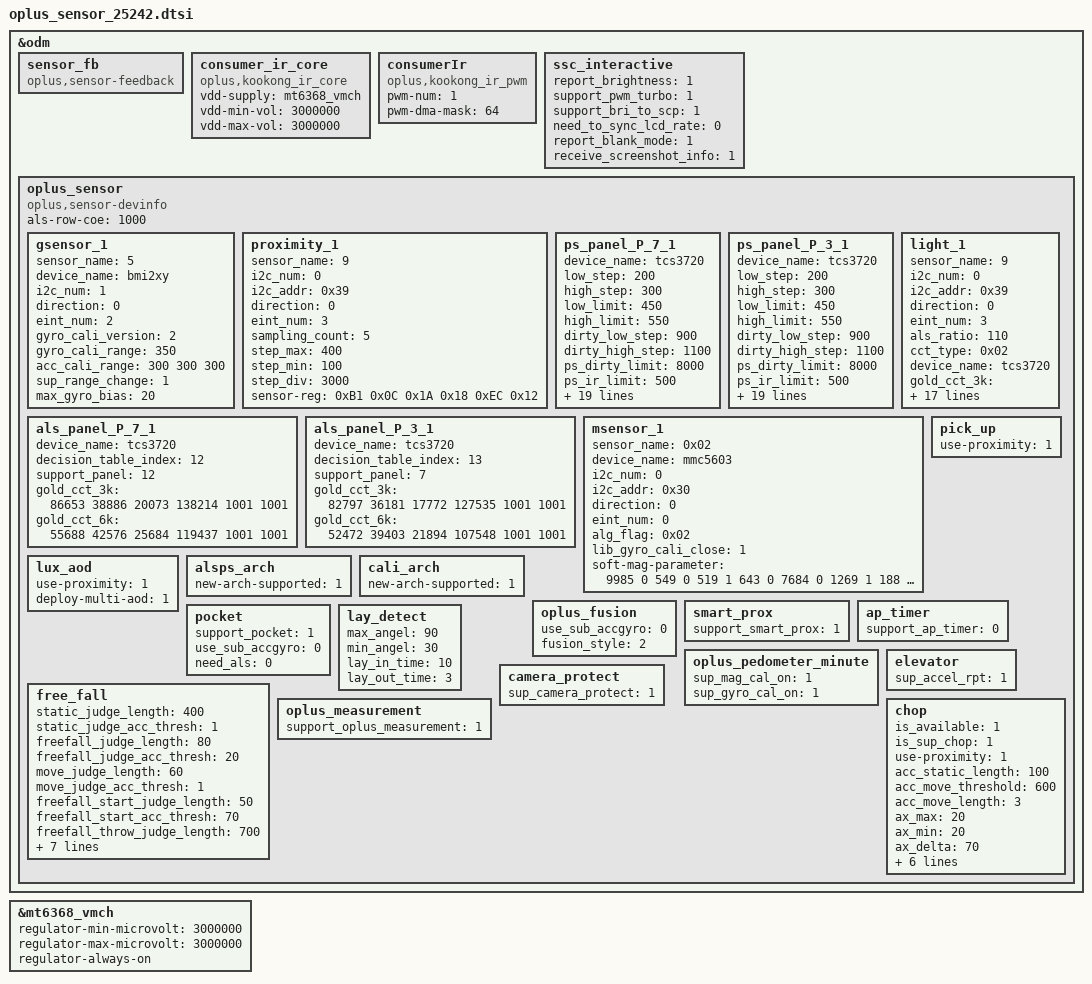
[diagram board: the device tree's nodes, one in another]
&odm {
	sensor_fb: sensor_fb {
		compatible = "oplus,sensor-feedback";
	};
	consumer_ir_core: consumer_ir_core {
		compatible = "oplus,kookong_ir_core";
		status = "okay";
		vdd-supply = <&mt6368_vmch>;
		vdd-min-vol = <3000000>;
		vdd-max-vol = <3000000>;
	};
	consumerIr: consumerIr {
		compatible = "oplus,kookong_ir_pwm";
		status = "okay";
		pwm-num = <1>;
		pwm-dma-mask = <64>;
	};
	ssc_interactive: ssc_interactive {
		report_brightness = <1>;
		support_pwm_turbo = <1>;
		support_bri_to_scp = <1>;
		need_to_sync_lcd_rate = <0>;
		report_blank_mode = <1>;
		receive_screenshot_info = <1>;
	};
	oplus_sensor:oplus_sensor {
		compatible = "oplus,sensor-devinfo";
		als-row-coe = <1000>;
		/* sensor start */
		/*
		enum {
			LIS3DH,
			LSM6DS3,
			BMI160,
			LIS2HH12,
			LSM6DSM,
			BMI2XY,
			LSM6DSO,
			ICM4X6XX,
			ICM4263X,
			ICM4N607,
			BMI22X,
			SC7A20,
			MC34X9,
		};
		*/
		gsensor_1: gsensor_1 {
			status = "okay";
			sensor_name = <5>;//BMI2XY
			device_name = "bmi2xy";
			i2c_num = <1>;
			direction = <0>;
			eint_num = <2>;
			gyro_cali_version= <2>;
			gyro_cali_range =<350>;
			acc_cali_range= <300 300 300>;
			sup_range_change = <1>;
			max_gyro_bias = <20>;
		};

		/*
		enum {
			AKM09911,
			MMC3530,
			MMC5603,
			MXG4300,
			AKM09918,
			AKM09919,
		};
		*/
		/* support_panel: search g_panel_node */
		/*enum panel_id{
			SAMSUNG = 1,
			BOE,
			TIANMA,
			NT36672C,
			HX83112F,
			TM,
			P_3,
			P_B,
			TD4377,
			ILI9883C,
			FT8057P,
			P_7,
			ILI7807S,
			DH_SOFT_LIGHT,
			NT36532W,
			HX,
			PANEL_NUM
		};*/
		proximity_1: proximity_1 {
			status = "okay";
			sensor_name = <9>;//TCS3720
			i2c_num = <0>;
			i2c_addr = <0x39>;
			direction = <0>;
			eint_num = <3>;
			sampling_count = <5>;
			step_max = <400>;
			step_min = <100>;
			step_div = <3000>;
			sensor-reg = <0xB1 0x0C 0x1A 0x18 0xEC 0x12>;
		};
		ps_panel_P_7_1: ps_panel_P_7_1 {
			status = "okay";
			device_name = "tcs3720";
			low_step = <200>;
			high_step = <300>;
			low_limit = <450>;
			high_limit = <550>;
			dirty_low_step = <900>;
			dirty_high_step = <1100>;
			ps_dirty_limit = <8000>;
			ps_ir_limit = <500>;
			ps_adjust_min = <0>;
			ps_adjust_max = <1250>;
			anti_shake_delta = <150>;
			dynamic_cali_max = <5000>;
			raw2offset_radio = <1000>;
			offset_max = <16000>;
			offset_range_min = <0>;
			offset_range_max = <65534>;
			force_cali_limit = <0>;
			cali_jitter_limit = <80>;
			cal_offset_margin = <8000>;
			60hz_psd_us = <2380>;
			90hz_psd_us = <2380>;
			120hz_psd_us = <2380>;
			ps_check_num = <3>;
			ps_mid_filter = <0>;
			need_to_sync_lcd_rate = <0>;
			dmc_flt_thr = <100>;
			ps_power_config = <14>;
		};
		ps_panel_P_3_1: ps_panel_P_3_1 {
			status = "okay";
			device_name = "tcs3720";
			low_step = <200>;
			high_step = <300>;
			low_limit = <450>;
			high_limit = <550>;
			dirty_low_step = <900>;
			dirty_high_step = <1100>;
			ps_dirty_limit = <8000>;
			ps_ir_limit = <500>;
			ps_adjust_min = <0>;
			ps_adjust_max = <1250>;
			anti_shake_delta = <150>;
			dynamic_cali_max = <5000>;
			raw2offset_radio = <1000>;
			offset_max = <16000>;
			offset_range_min = <0>;
			offset_range_max = <65534>;
			force_cali_limit = <0>;
			cali_jitter_limit = <80>;
			cal_offset_margin = <8000>;
			60hz_psd_us = <2380>;
			90hz_psd_us = <2380>;
			120hz_psd_us = <2380>;
			ps_check_num = <3>;
			ps_mid_filter = <0>;
			need_to_sync_lcd_rate = <0>;
			dmc_flt_thr = <100>;
			ps_power_config = <14>;
		};
		light_1: light_1 {
			status = "okay";
			sensor_name = <9>;//TCS3720
			i2c_num = <0>;
			i2c_addr = <0x39>;
			direction = <0>;
			eint_num = <3>;
			als_ratio = <110>;
			cct_type = <0x02>; //0x01 CCT_NORMAL 0x02 CCT_WISE
			device_name = "tcs3720";
			gold_cct_3k = <86653 38886 20073 138214 1001 1001>;
			gold_cct_6k = <55688 42576 25684 119437 1001 1001>;
			lb_bri_max = <4096>;
			ir_ratio = <10>; // *1000
			als_delay = <390>;
			als_delay_60hz = <153>;
			als_delay_90hz = <290>;
			als_delay_120hz = <242>;
			available_sensor = <14>;
			gold_cct_factor = <1000 1000 1000 1000 1000 1000>;
			high_pwm_cct = <1>;
			als_timer_ms = <100>;
			als_buffer_length = <2>;
			need_gain_cali = <1>;
                        scale_gain = <512>;
			fifo_sample_time_switch = <1>;
		};
		als_panel_P_7_1: als_panel_P_7_1 {
			status = "okay";
			device_name = "tcs3720";
			decision_table_index = <12>;
			support_panel = <12>; // 1-SAMSUNG, 2-BOE, 3-TIANMA, 4-NT36672C, 5-HX83112F, 6-TM, 7-P_3, 8-P_B, 9-TD4377, 10-ILI9883C, 11-FT8057P, 12-P_7
			gold_cct_3k = <86653 38886 20073 138214 1001 1001>;
			gold_cct_6k = <55688 42576 25684 119437 1001 1001>;
		};
		als_panel_P_3_1: als_panel_P_3_1 {
			status = "okay";
			device_name = "tcs3720";
			decision_table_index = <13>;
			support_panel = <7>; // 1-SAMSUNG, 2-BOE, 3-TIANMA, 4-NT36672C, 5-HX83112F, 6-TM, 7-P_3, 8-P_B, 9-TD4377, 10-ILI9883C, 11-FT8057P, 12-P_7
			gold_cct_3k = <82797 36181 17772 127535 1001 1001>;
			gold_cct_6k = <52472 39403 21894 107548 1001 1001>;
		};
		msensor_1: msensor_1 {
			status = "okay";
			sensor_name = <0x02>; // MMC5603
			device_name = "mmc5603";
			i2c_num = <0>;
			i2c_addr = <0x30>;
			direction = <0>;
			eint_num = <0>;
			alg_flag = <0x02>;
			lib_gyro_cali_close = <1>;
			soft-mag-parameter = <9985 0 549 0 519 1 643 0 7684 0 1269 1 188 0 145 1 10483 0>;
		};
		pick_up: pick_up {
			status = "okay";
			use-proximity = <1>;
		};
		lux_aod: lux_aod {
			status = "okay";
			use-proximity = <1>;
			deploy-multi-aod = <1>;
		};
		alsps_arch: alsps_arch {
			status = "okay";
			new-arch-supported = <1>;
		};
		cali_arch: cali_arch {
			status = "okay";
			new-arch-supported = <1>;
		};
		oplus_fusion: oplus_fusion {
			status = "okay";
			use_sub_accgyro = <0>;
			fusion_style = <2>; // 0:vendor fusion; 1:oppo fusion; 2:mix fusion
		};
		smart_prox: smart_prox {
			status = "okay";
			support_smart_prox = <1>;
		};
		ap_timer: ap_timer {
			status = "okay";
			support_ap_timer = <0>;
		};
		pocket: pocket {
			status = "okay";
			support_pocket = <1>;
			use_sub_accgyro = <0>;
			need_als = <0>;
		};
		lay_detect: lay_detect{
			status = "okay";
			max_angel = <90>;
			min_angel = <30>;
			lay_in_time = <10>;
			lay_out_time = <3>;
		};
		oplus_pedometer_minute: oplus_pedometer_minute{
			status = "okay";
			sup_mag_cal_on = <1>;
			sup_gyro_cal_on = <1>;
		};
		free_fall: free_fall{
			status = "okay";
			static_judge_length = <400>;
			static_judge_acc_thresh = <1>;
			freefall_judge_length = <80>;
			freefall_judge_acc_thresh = <20>;
			move_judge_length = <60>;
			move_judge_acc_thresh = <1>;
			freefall_start_judge_length  = <50>;
			freefall_start_acc_thresh = <70>;
			freefall_throw_judge_length = <700>;
			freefall_throw_acc_thresh = <50>;
			freefall_end_acc_thresh = <30>;
			freefall_valid_time_length = <1000>;
			freefall_peek_time_length = <800>;
			freefall_peek_acc_thresh = <60>;
			freefall_material_thresh = <900>;
			valid_peek_interval_thresh = <10000>;
		};
		oplus_measurement: oplus_measurement{
			status = "okay";
			support_oplus_measurement = <1>;
		};

		elevator: elevator{
			status = "okay";
			sup_accel_rpt = <1>;
		};
		chop: chop {
			status = "okay";
			is_available = <1>;
			is_sup_chop = <1>;
			use-proximity = <1>;

			acc_static_length = <100>;
			acc_move_threshold = <600>;
			acc_move_length = <3>;
			ax_max = <20>;
			ax_min = <20>;
			ax_delta = <70>;
			ax_peek_cnt = <1>;
			ax_extra_cnt = <2>;
			chop_cnt = <2>;
			chop_between_ms = <250>;
			chop_timeout_ms = <700>;
			chop_buffer_size = <10>;
		};
		camera_protect: camera_protect {
			status = "okay";
			sup_camera_protect = <1>;
		};
	};
/* sensor end */
};

&mt6368_vmch {
	regulator-min-microvolt = <3000000>;
	regulator-max-microvolt = <3000000>;
	regulator-always-on;
};
